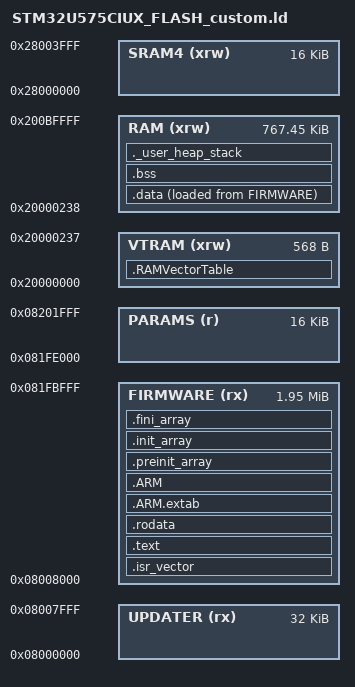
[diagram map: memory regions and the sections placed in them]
/*
******************************************************************************
**
**  File        : LinkerScript.ld
**
**  Author      : STM32CubeIDE
**
**  Abstract    : Linker script for STM32U575xI Device from STM32U5 series
**                      2048Kbytes FLASH
**                      784Kbytes RAM
**
**                Set heap size, stack size and stack location according
**                to application requirements.
**
**                Set memory bank area and size if external memory is used.
**
**  Target      : STMicroelectronics STM32
**
**  Distribution: The file is distributed as is without any warranty
**                of any kind.
**
*****************************************************************************
** @attention
**
** Copyright (c) 2022 STMicroelectronics.
** All rights reserved.
**
** This software is licensed under terms that can be found in the LICENSE file
** in the root directory of this software component.
** If no LICENSE file comes with this software, it is provided AS-IS.
**
*****************************************************************************
*/

/* Entry Point */
ENTRY(Reset_Handler)

/* Highest address of the user mode stack */
_estack = ORIGIN(RAM) + LENGTH(RAM);	/* end of "RAM" Ram type memory */

_Min_Heap_Size = 0x200 ;	/* required amount of heap  */
_Min_Stack_Size = 0x400 ;	/* required amount of stack */

/* Memories definition */
MEMORY
{
  VTRAM (xrw)     : ORIGIN = 0x20000000, LENGTH = 0x238  /* First part of RAM is reserved to the vector table */
  RAM	(xrw)	  : ORIGIN = 0x20000238,	LENGTH = 768K - 568
  SRAM4	(xrw)	  : ORIGIN = 0x28000000,	LENGTH = 16K
/*  FLASH	(rx)	: ORIGIN = 0x08000000,	LENGTH = 2048K*/
  UPDATER (rx)    : ORIGIN = 0x08000000, LENGTH = 32K
  FIRMWARE (rx)   : ORIGIN = 0x08008000, LENGTH = 2000K
  PARAMS (r)      : ORIGIN = 0x081FE000, LENGTH = 16K
}

REGION_ALIAS( "FLASH", FIRMWARE );

_main_app_start_address      = 0x08008000;
_slaves_table_start_address  = 0x0000;
_logger_start_address        = 0x2000;
_pressure_start_address      = 0x100000;/*0x200000;*/
_modbus_start_address        = 0x300000;/*0x400000;*/
_fwupdate_start_address      = 0x08104000;
_params_start_address        = 0x081FC000;
_main_app_size      		 = 2000K;
_fwupdate_size        		 = 992K;
_logger_meas_size 			 = 3072K;
_frame_tx_size               = 4088K;
_pressure_meas_size 		 = 64K;
_modbus_meas_size 		     = 64K;
_logger_event_size  		 = 40K;        /* datalogger events size   */
_params_size        		 = 16K;

/* Sections */
SECTIONS
{
  /* The startup code into "FLASH" Rom type memory */
  .isr_vector :
  {
    KEEP(*(.isr_vector)) /* Startup code */
  } >FLASH

  /* The program code and other data into "FLASH" Rom type memory */
  .text :
  {
    *(.text)           /* .text sections (code) */
    *(.text*)          /* .text* sections (code) */
    *(.glue_7)         /* glue arm to thumb code */
    *(.glue_7t)        /* glue thumb to arm code */
    *(.eh_frame)

    KEEP (*(.init))
    KEEP (*(.fini))

    _etext = .;        /* define a global symbols at end of code */
  } >FLASH

  /* Constant data into "FLASH" Rom type memory */
  .rodata :
  {
    *(.rodata)         /* .rodata sections (constants, strings, etc.) */
    *(.rodata*)        /* .rodata* sections (constants, strings, etc.) */
  } >FLASH

  .ARM.extab :
  {
    *(.ARM.extab* .gnu.linkonce.armextab.*)
  } >FLASH

  .ARM :
  {
    __exidx_start = .;
    *(.ARM.exidx*)
    __exidx_end = .;
  } >FLASH

  .preinit_array :
  {
    PROVIDE_HIDDEN (__preinit_array_start = .);
    KEEP (*(.preinit_array*))
    PROVIDE_HIDDEN (__preinit_array_end = .);
  } >FLASH

  .init_array :
  {
    PROVIDE_HIDDEN (__init_array_start = .);
    KEEP (*(SORT(.init_array.*)))
    KEEP (*(.init_array*))
    PROVIDE_HIDDEN (__init_array_end = .);
  } >FLASH

  .fini_array :
  {
    PROVIDE_HIDDEN (__fini_array_start = .);
    KEEP (*(SORT(.fini_array.*)))
    KEEP (*(.fini_array*))
    PROVIDE_HIDDEN (__fini_array_end = .);
  } >FLASH

  /* Used by the startup to initialize data */
  _sidata = LOADADDR(.data);

  /* Initialized data sections into "RAM" Ram type memory */
  .data :
  {
    _sdata = .;        /* create a global symbol at data start */
    *(.data)           /* .data sections */
    *(.data*)          /* .data* sections */
    *(.RamFunc)        /* .RamFunc sections */
    *(.RamFunc*)       /* .RamFunc* sections */

    _edata = .;        /* define a global symbol at data end */
  } >RAM AT> FLASH

  /* Uninitialized data section into "RAM" Ram type memory */
  .bss :
  {
    /* This is used by the startup in order to initialize the .bss section */
    _sbss = .;         /* define a global symbol at bss start */
    __bss_start__ = _sbss;
    *(.bss)
    *(.bss*)
    *(COMMON)

    _ebss = .;         /* define a global symbol at bss end */
    __bss_end__ = _ebss;
  } >RAM

  /* User_heap_stack section, used to check that there is enough "RAM" Ram type memory left */
  ._user_heap_stack :
  {
    . = ALIGN(8);
    PROVIDE ( end = . );
    PROVIDE ( _end = . );
    . = . + _Min_Heap_Size;
    . = . + _Min_Stack_Size;
    . = ALIGN(8);
  } >RAM

  /* Remove information from the compiler libraries */
  /DISCARD/ :
  {
    libc.a ( * )
    libm.a ( * )
    libgcc.a ( * )
  }

  .ARM.attributes 0 : { *(.ARM.attributes) }
  /* RAM space for the vector table */
  .RAMVectorTable(NOLOAD): {*(.RAMVectorTable)} >VTRAM
}
